# PIC18F06Q20 register map
Vendor: Microchip
Architecture 18xxxx. Special function registers and configuration words.
Registers are 8-bit, read-write, reset 0x0 unless marked. A register's access mark holds for its fields unless they carry their own. Addresses are absolute, and some are shared; only a register's first bit layout is shown; lines under a group give offsets from that group; [hi:lo] are bit positions; {n}, {i} and the like mark numbered series; 'fields as' and 'values as' point back to an identical list; <NAME> marks a mode.

## Further device data
pins=1: AVDD/VDD/VDDIO1; 2: CLKIN/OSC1/SOSCI/ANA5/IOCA5/RA5; 3: CLKOUT/OSC2/SOSCO/ANA4/IOCA4/RA4; 4: VPP/MCLR_n/ICDMCLR_n/IOCA3/RA3; 5: SMB_I2C/ANC5/IOCC5/RC5; 6: SMB_I2C/ANC4/IOCC4/RC4; 7: ANC3/IOCC3/RC3; 8: VDDIO2; 9: MVIO_VDDIO2/LV_I3C/SMB_I2C/IOCC1/RC1; 10: MVIO_VDDIO2/LV_I3C/SMB_I2C/IOCC0/RC0; 11: VREF-/ANA2/IOCA2/RA2; 12: VREF+/ICSPCLK/ICDCLK/ANA1/IOCA1/RA1; 13: ICSPDAT/ICDDAT/ANA0/IOCA0/RA0; 14: AVSS/VSS, interrupts=0 SW — Software Interrupt; 1 INT0 — External Interrupt 0; 2 INT1 — External Interrupt 1; 3 INT2 — External Interrupt 2; 4 DMA1SCNT — DMA1 Source Count Interrupt; 5 DMA1DCNT — DMA1 Destination Count Interrupt; 6 DMA1OR — DMA1 Overflow Interrupt; 7 DMA1A — DMA1 Abort Interrupt; 8 DMA2SCNT — DMA2 Source Count Interrupt; 9 DMA2DCNT — DMA2 Destination Count Interrupt; 10 DMA2OR — DMA2 Overflow Interrupt; 11 DMA2A — DMA2 Abort Interrupt; 12 DMA3SCNT — DMA3 Source Count Interrupt; 13 DMA3DCNT — DMA3 Destination Count Interrupt; 14 DMA3OR — DMA3 Overflow Interrupt; 15 DMA3A — DMA3 Abort Interrupt; 16 DMA4SCNT — DMA4 Source Count Interrupt; 17 DMA4DCNT — DMA4 Destination Count Interrupt; 18 DMA4OR — DMA4 Overflow Interrupt; 19 DMA4A — DMA4 Abort Interrupt; 20 NVM — NVM Interrupt; 21 CRC — CRC Interrupt; 22 SCAN — Scanner Interrupt; 23 ACT — Active Clock Tuning Interrupt; 24 CSW — Clock Switch Interrupt; 25 OSF — Oscillator Failure Interrupt; 26 VDDIO2 — VDDIO2 Interrupt; 28 IOC — Interrupt on Change; 29 TMR0 — Timer0 Interrupt; 30 TMR1 — Timer1 Interrupt; 31 TMR1G — Timer1 Gate Interrupt; 32 TMR2 — Timer2 Interrupt; 33 TMR4 — Timer4 Interrupt; 34 TU16A — 16-Bit Universal Timer A Interrupt; 35 TU16B — 16-Bit Universal Timer B Interrupt; 36 CCP1 — CCP1 Interrupt; 37 CCP2 — CCP2 Interrupt; 38 PWM1P — PWM1 Period Interrupt; 39 PWM1 — PWM1 Interrupt; 40 PWM2P — PWM2 Period Interrupt; 41 PWM2 — PWM2 Interrupt; 42 CWG1 — CWG1 Interrupt; 43 CLC1 — CLC1 Interrupt; 44 CLC2 — CLC2 Interrupt; 45 CLC3 — CLC3 Interrupt; 46 CLC4 — CLC4 Interrupt; 47 IOCSR — Signal Routing Port Interrupt on Change; 48 U1RX — UART1 Receive Interrupt; 49 U1TX — UART1 Transmit Interrupt; 50 U1 — UART1 Interrupt; 51 U1E — UART1 Error Interrupt; 52 U2RX — UART2 Receive Interrupt; 53 U2TX — UART2 Transmit Interrupt; 54 U2 — UART2 Interrupt; 55 U2E — UART2 Error Interrupt; 56 SPI1RX — SPI1 Receive Interrupt; 57 SPI1TX — SPI1 Transmit Interrupt; 58 SPI1 — SPI1 Interrupt; 59 I2C1RX — I2C1 Receive Interrupt; 60 I2C1TX — I2C1 Transmit Interrupt; 61 I2C1 — I2C1 Interrupt; 62 I2C1E — I2C1 Error Interrupt; 64 I3C1RX — I3C1 Receive Interrupt; 65 I3C1TX — I3C1 Transmit Interrupt; 66 I3C1 — I3C1 General Interrupt; 67 I3C1E — I3C1 Error Interrupt; 68 I3C1R — I3C1 Reset Interrupt; 77 HLVD — HLVD Interrupt; 78 AD — ADC Interrupt; 79 ADT — ADC Threshold Interrupt

## dma
0x40 DMASELECT — DMA instance selection register
  [2:0] SLCT
0x41 DMAnBUF ro reset not defined — DMA data buffer (power-on value xxxxxxxx)
  [7:0] BUF
0x42 DMAnDCNTL
  [7:0] DCNT
0x43 DMAnDCNTH
  [3:0] DCNT
0x44 DMAnDPTRL ro
  [7:0] DPTR
0x45 DMAnDPTRH ro
  [7:0] DPTR
0x46 DMAnDSZL reset not defined — (power-on value xxxxxxxx)
  [7:0] DSZ
0x47 DMAnDSZH
  [3:0] DSZ
0x48 DMAnDSAL reset not defined — (power-on value xxxxxxxx)
  [7:0] DSA
0x49 DMAnDSAH
  [7:0] DSA
0x4A DMAnSCNTL
  [7:0] SCNT
0x4B DMAnSCNTH
  [3:0] SCNT
0x4C DMAnSPTRL ro
  [7:0] SPTR
0x4D DMAnSPTRH ro
  [7:0] SPTR
0x4E DMAnSPTRU ro
  [5:0] SPTR
0x4F DMAnSSZL
  [7:0] SSZ
0x50 DMAnSSZH
  [3:0] SSZ
0x51 DMAnSSAL
  [7:0] SSA
0x52 DMAnSSAH
  [7:0] SSA
0x53 DMAnSSAU
  [5:0] SSA
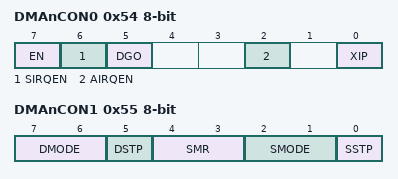
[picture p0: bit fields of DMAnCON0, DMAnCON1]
0x54 DMAnCON0 — DMA control register 0
  [7] EN, [6] SIRQEN, [5] DGO, [2] AIRQEN, [0] XIP ro
0x55 DMAnCON1 — DMA control register 1
  [7:6] DMODE, [5] DSTP, [4:3] SMR, [2:1] SMODE, [0] SSTP
0x56 DMAnAIRQ — DMA abort trigger selection register
  [7:0] AIRQ
0x57 DMAnSIRQ — DMA start trigger selection register
  [7:0] SIRQ
